VERSION "HIPBNYYYYYYYYYYYYYYYYYYYYYYYYYYYYYYYYYYYYY/4/%%%/4/'%**4YYY///"

NS_ :

BS_:

BU_:

BO_ 258 CAN02: 8 Vector__XXX
 SG_ VehicleOdometer : 40|24@1+ (1,0) [0|999000] "km" Vector__XXX
 SG_ VehicleSpeed : 0|16@1+ (1,0) [0|512] "km/h" Vector__XXX

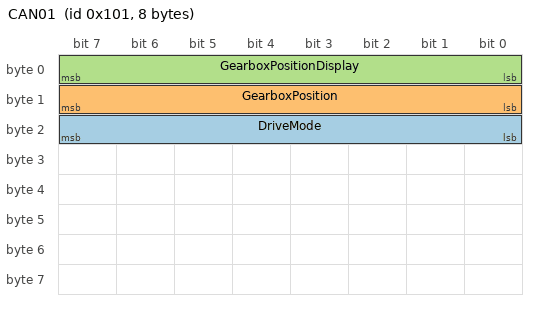
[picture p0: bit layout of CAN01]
BO_ 257 CAN01: 8 Vector__XXX
 SG_ DriveMode : 16|8@1+ (1,0) [0|255] "" Vector__XXX
 SG_ GearboxPosition : 8|8@1+ (1,0) [0|8] "" Vector__XXX
 SG_ GearboxPositionDisplay : 0|8@1+ (1,0) [0|15] "" Vector__XXX

BA_DEF_  "BusType" STRING ;
BA_DEF_DEF_  "BusType" "CAN";
VAL_ 257 DriveMode 10 "Normal" 12 "ECO" 13 "SPORT" ;
